# MDR1901VC1 register map
Vendor: Milandr; Series: ARMCM3; File version: 2.0
CPU: CM3 r2p1, little endian, no MPU, no FPU, 3 interrupt priority bits
Registers are 32-bit, read-write, reset 0x0 unless marked. A register's access mark holds for its fields unless they carry their own. Offsets are from the block's base; [hi:lo] are bit positions; {n}, {i} and the like mark numbered series; 'fields as' and 'values as' point back to an identical list.

## MDR_RST_CLOCK — CLock Control
Base 0x40020000
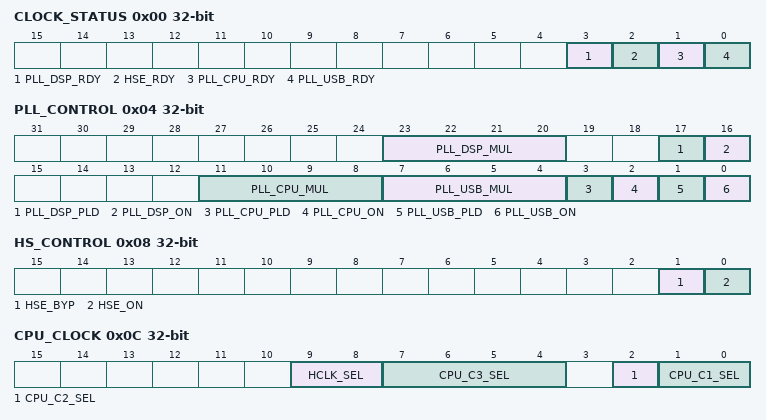
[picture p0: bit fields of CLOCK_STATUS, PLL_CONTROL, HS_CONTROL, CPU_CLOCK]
0x00 CLOCK_STATUS ro
  [3] PLL_DSP_RDY — DSP PLL ready
    0=NotReady (PLL not ready); 1=Ready (PLL ready)
  [2] HSE_RDY — HSE generator ready
    0=NotReady (HSE not ready); 1=Ready (HSE ready)
  [1] PLL_CPU_RDY — PLL CPU ready
    0=NotReady (PLL not ready); 1=Ready (PLL ready)
  [0] PLL_USB_RDY — PLL USP ready
    0=NotReady (PLL not ready); 1=Ready (PLL ready)
0x04 PLL_CONTROL
  [23:20] PLL_DSP_MUL — PLL DSP Mul, [x2 .. x16]
    0=PLL mul x1; {v}=x{v+1} (PLL mul x{v+1}) (v=1..8); 9=PLL mul x10; 10=PLL mul x11; {v}=x{v+1} (PLL mul x{v+1}) (v=11..15)
  [17] PLL_DSP_PLD — PLL DSP Restart
    0=RestartOff (PLL restart inactive); 1=DoRestart (PLL Do Restart)
  [16] PLL_DSP_ON — PLL DSP Enable
    0=Off (PLL Off); 1=On (PLL On)
  [11:8] PLL_CPU_MUL — PLL CPU Mul, [x1 .. x16]
    values as PLL_DSP_MUL
  [7:4] PLL_USB_MUL — PLL USB Mul, [x1 .. x16]
    values as PLL_DSP_MUL
  [3] PLL_CPU_PLD — PLL CPU Restart
    values as PLL_DSP_PLD
  [2] PLL_CPU_ON — PLL CPU Enable
    0=Off (PLL Off); 1=On (PLL On)
  [1] PLL_USB_PLD — PLL USB Restart
    values as PLL_DSP_PLD
  [0] PLL_USB_ON — PLL USB Enable
    0=Off (PLL Off); 1=On (PLL On)
0x08 HS_CONTROL — HSE Generator Control
  [1] HSE_BYP — HSE Bypass Mode
    0=Off (HSE forms Clock from external oscillator); 1=On (HSE passes Clock from external generator)
  [0] HSE_ON — HSE Enable
    0=Off (HSE Off); 1=On (HSE On)
0x0C CPU_CLOCK — CPU Clock Control
  [9:8] HCLK_SEL — Select Clock for CPU
    0=HSI (CPU clock is HSI); 1=CPU_C3 (CPU clock is CPU_C3 output); 2=LSE (CPU clock is LSE); 3=LSI (CPU clock is LSI)
  [7:4] CPU_C3_SEL — CPU_C2 mux output freq devider, [/1, /2, /4 .. /256]
    0b0xxx=div1 (div by 1); 8=div2 (div by 2); 9=div4 (div by 4); 10=div8 (div by 8); 11=div16 (div by 16); 12=div32 (div by 32); 13=div64 (div by 64); 14=div128 (div by 128); 15=div256 (div by 256)
  [2] CPU_C2_SEL — CPU_C2 mux freq select
    0=CPU_C1 (Freq from CPU_C1 mux direct); 1=PLLCPUo (Freq from CPU_C1 mux through PLL)
  [1:0] CPU_C1_SEL — CPU_C1 mux freq select
    0=HSI (CPU_C1 output is HSI); 1=HSI/2 (CPU_C1 output is HSI/2); 2=HSE (CPU_C1 output is HSE); 3=HSE/2 (CPU_C1 output is HSE/2)
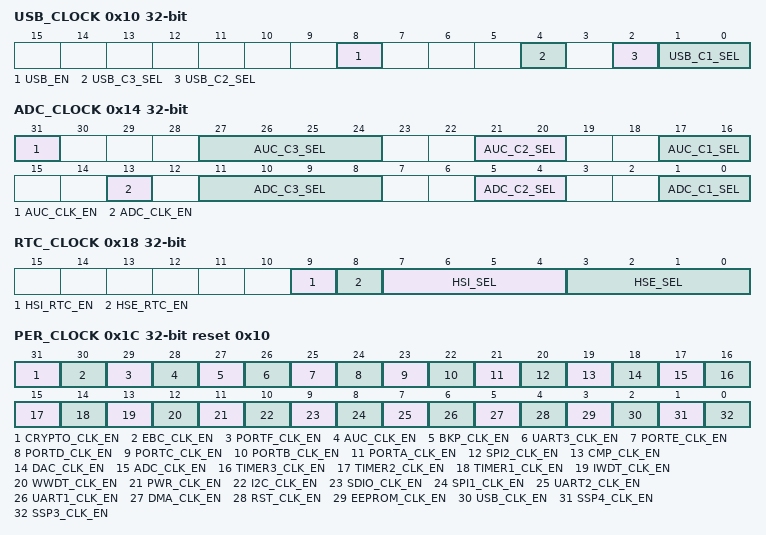
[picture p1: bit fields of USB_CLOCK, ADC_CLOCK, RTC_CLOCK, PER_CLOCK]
0x10 USB_CLOCK — USB Clock Control
  [8] USB_EN — USB Clock Enable
    0=Off (Clock Disabled); 1=On (Clock Enabled)
  [4] USB_C3_SEL — USB_C3 Input Select
    0=USB_C2 (C3 Input is freq from C2); 1=USB_C2_div2 (C3 Input is freq from C2/2)
  [2] USB_C2_SEL — USB_C2 mux freq select
    0=USB_C1 (Freq from CPU_C1 mux direct); 1=PLLUSBo (Freq from CPU_C1 mux through PLL_USB)
  [1:0] USB_C1_SEL — USB_C1 mux freq select
    0=HSI (USB_C1 output is HSI); 1=HSI/2 (USB_C1 output is HSI/2); 2=HSE (USB_C1 output is HSE); 3=HSE/2 (USB_C1 output is HSE/2)
0x14 ADC_CLOCK — ADC Clock Control
  [31] AUC_CLK_EN — AudioCodec Clock Enable
    0=Off (AUC clock disabled); 1=On (AUC clock enabled)
  [27:24] AUC_C3_SEL — AUC_C3 mux input select
    values as CPU_CLOCK.CPU_C3_SEL
  [21:20] AUC_C2_SEL — AUC_C2 mux input select
    0=AUC_C1 (AUC_C2 output is AUC_C1 select); 1=PLLCPUo (AUC_C2 output is PLLCPUo); 2=PLLUSBo (AUC_C2 output is PLLUSBo); 3=No signal from AUC_C2
  [17:16] AUC_C1_SEL — AUC_C1 mux input select
    values as CPU_CLOCK.CPU_C1_SEL
  [13] ADC_CLK_EN — ADC Clock Enable
    0=Off (ADC clock disabled); 1=On (ADC clock enabled)
  [11:8] ADC_C3_SEL — ADC_C2 mux output freq devider, [/1, /2, /4 .. /256]
    values as CPU_CLOCK.CPU_C3_SEL
  [5:4] ADC_C2_SEL — ADC_C2 mux freq select
    0=LSE (ADC_C2 output is LSE); 1=LSI (ADC_C2 output is LSI); 2=ADC_C1 (ADC_C2 output is ADC_C1); 3=HSI_C1 (ADC_C2 output is HSI_C1)
  [1:0] ADC_C1_SEL — ADC_C1 mux freq select
    0=CPU_C1 (ADC_C1 output is CPU_C1); 1=USB_C1 (ADC_C1 output is USB_C1); 2=CPU_C2 (ADC_C1 output is CPU_C2); 3=USB_C2 (ADC_C1 output is USB_C2)
0x18 RTC_CLOCK — RTC Clock Control
  [9] HSI_RTC_EN — RTC HSI Clock enable
    0=Off (RTC HSI Clock Disabled); 1=On (RTC HSI Clock Enabled)
  [8] HSE_RTC_EN — RTC HSE Clock enable
    0=Off (RTC HSE Clock Disabled); 1=On (RTC HSE Clock Enabled)
  [7:4] HSI_SEL — RTC HSI freq devider, [/1, /2, /4 .. /256]
    values as CPU_CLOCK.CPU_C3_SEL
  [3:0] HSE_SEL — RTC HSE freq devider, [/1, /2, /4 .. /256]
    values as CPU_CLOCK.CPU_C3_SEL
0x1C PER_CLOCK reset 0x10 — Peripherials Clock Control
  [all] fields
    0=Off (Clock Disabled); 1=On (Clock Enabled)
  [31] CRYPTO_CLK_EN — CRYPTO Clock Enable
  [30] EBC_CLK_EN — External Bus Clock Enable
  [29] PORTF_CLK_EN — GPIO PORT_F Clock Enable
  [28] AUC_CLK_EN — AUC Clock Enable
  [27] BKP_CLK_EN — Backup Clock Enable
  [26] UART3_CLK_EN — UART3 Clock Enable
  [25] PORTE_CLK_EN — GPIO PORT_E Clock Enable
  [24] PORTD_CLK_EN — GPIO PORT_D Clock Enable
  [23] PORTC_CLK_EN — GPIO PORT_C Clock Enable
  [22] PORTB_CLK_EN — GPIO PORT_B Clock Enable
  [21] PORTA_CLK_EN — GPIO PORT_A Clock Enable
  [20] SPI2_CLK_EN — SPI2 Clock Enable
  [19] CMP_CLK_EN — Comparator Clock Enable
  [18] DAC_CLK_EN — DAC Clock Enable
  [17] ADC_CLK_EN — ADC Clock Enable
  [16] TIMER3_CLK_EN — TIMER3 Clock Enable
  [15] TIMER2_CLK_EN — TIMER2 Clock Enable
  [14] TIMER1_CLK_EN — TIMER1 Clock Enable
  [13] IWDT_CLK_EN — IWDT Clock Enable
  [12] WWDT_CLK_EN — WWDT Clock Enable
  [11] PWR_CLK_EN — Power Clock Enable
  [10] I2C_CLK_EN — I2C Clock Enable
  [9] SDIO_CLK_EN — SDIO Clock Enable
  [8] SPI1_CLK_EN — SPI1 Clock Enable
  [7] UART2_CLK_EN — UART2 Clock Enable
  [6] UART1_CLK_EN — UART1 Clock Enable
  [5] DMA_CLK_EN — DMA Clock Enable
  [4] RST_CLK_EN — RST Clock Enable
  [3] EEPROM_CLK_EN — EEPROM Controller Clock Enable
  [2] USB_CLK_EN — USB Clock Enable
  [1] SSP4_CLK_EN — SSP4 Clock Enable
  [0] SSP3_CLK_EN — SSP3 Clock Enable
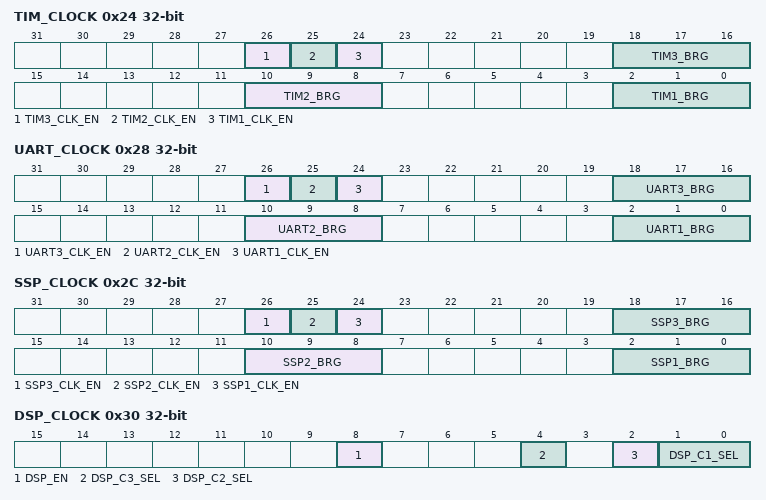
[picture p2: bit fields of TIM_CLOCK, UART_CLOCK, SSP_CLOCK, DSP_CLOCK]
0x24 TIM_CLOCK — Timer's Clock Control
  [26] TIM3_CLK_EN — TIM3_CLOCK enable
    0=Off (Timer3 Clock Disabled); 1=On (Timer3 Clock Enabled)
  [25] TIM2_CLK_EN — TIM2_CLOCK enable
    0=Off (Timer2 Clock Disabled); 1=On (Timer2 Clock Enabled)
  [24] TIM1_CLK_EN — TIM1_CLOCK enable
    0=Off (Timer1 Clock Disabled); 1=On (Timer1 Clock Enabled)
  [18:16] TIM3_BRG — HCLK freq divider to get TIM3_CLOCK, [/1, /2, /4 .. /128]
    0=div1 (div by 1); 1=div2 (div by 2); 2=div4 (div by 4); 3=div8 (div by 8); 4=div16 (div by 16); 5=div32 (div by 32); 6=div64 (div by 64); 7=div128 (div by 128)
  [10:8] TIM2_BRG — HCLK freq divider to get TIM2_CLOCK, [/1, /2, /4 .. /128]
    values as TIM3_BRG
  [2:0] TIM1_BRG — HCLK freq divider to get TIM1_CLOCK, [/1, /2, /4 .. /128]
    values as TIM3_BRG
0x28 UART_CLOCK — UART's Clock Control
  [26] UART3_CLK_EN — UART3_CLOCK enable
    0=Off (UART3 Clock Disabled); 1=On (UART3 Clock Enabled)
  [25] UART2_CLK_EN — UART2_CLOCK enable
    0=Off (UART2 Clock Disabled); 1=On (UART2 Clock Enabled)
  [24] UART1_CLK_EN — UART1_CLOCK enable
    0=Off (UART1 Clock Disabled); 1=On (UART1 Clock Enabled)
  [18:16] UART3_BRG — HCLK freq divider to get UART3_CLOCK, [/1, /2, /4 .. /128]
    values as TIM_CLOCK.TIM3_BRG
  [10:8] UART2_BRG — HCLK freq divider to get UART2_CLOCK, [/1, /2, /4 .. /128]
    values as TIM_CLOCK.TIM3_BRG
  [2:0] UART1_BRG — HCLK freq divider to get UART1_CLOCK, [/1, /2, /4 .. /128]
    values as TIM_CLOCK.TIM3_BRG
0x2C SSP_CLOCK — SSP's Clock Control
  [26] SSP3_CLK_EN — SSP3_CLOCK Enable
    0=Off (SSP3 Clock Disabled); 1=On (SSP3 Clock Enabled)
  [25] SSP2_CLK_EN — SSP2_CLOCK Enable
    0=Off (SSP2 Clock Disabled); 1=On (SSP2 Clock Enabled)
  [24] SSP1_CLK_EN — SSP1_CLOCK Enable
    0=Off (SSP1 Clock Disabled); 1=On (SSP1 Clock Enabled)
  [18:16] SSP3_BRG — HCLK freq divider to get SSP3_CLOCK, [/1, /2, /4 .. /128]
    values as TIM_CLOCK.TIM3_BRG
  [10:8] SSP2_BRG — HCLK freq divider to get SSP2_CLOCK, [/1, /2, /4 .. /128]
    values as TIM_CLOCK.TIM3_BRG
  [2:0] SSP1_BRG — HCLK freq divider to get SSP1_CLOCK, [/1, /2, /4 .. /128]
    values as TIM_CLOCK.TIM3_BRG
0x30 DSP_CLOCK — DSP Clock Control
  [8] DSP_EN — DSP Clock Enable
    0=Off (Clock Disabled); 1=On (Clock Enabled)
  [4] DSP_C3_SEL — DSP_C3 Input Select
    0=DSP_C2 (C3 Input is freq from C2); 1=DSP_C2_div2 (C3 Input is freq from C2/2)
  [2] DSP_C2_SEL — DSP_C2 mux freq select
    0=DSP_C1 (Freq from DSP_C1 mux direct); 1=PLLDSPo (Freq from CPU_C1 mux through PLL_DSP)
  [1:0] DSP_C1_SEL — DSP_C1 mux freq select
    0=HSI (DSP_C1 output is HSI); 1=HSI/2 (DSP_C1 output is HSI/2); 2=HSE (DSP_C1 output is HSE); 3=HSE/2 (DSP_C1 output is HSE/2)
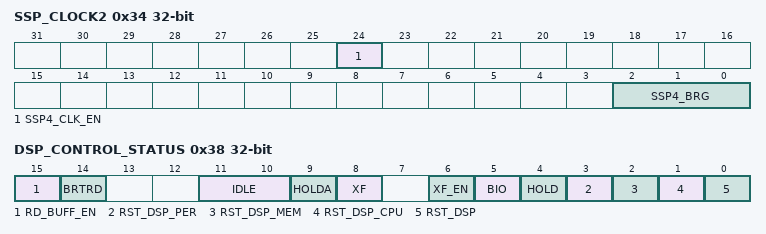
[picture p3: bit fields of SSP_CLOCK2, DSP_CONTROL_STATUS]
0x34 SSP_CLOCK2 — SSP Clock Control 2
  [24] SSP4_CLK_EN — SSP4 Clock Enable
    0=Off (SSP4 Clock Disabled); 1=On (SSP4 Clock Enabled)
  [2:0] SSP4_BRG — HCLK freq divider to get SSP4_CLOCK, [/1, /2, /4 .. /128]
    values as TIM_CLOCK.TIM3_BRG
0x38 DSP_CONTROL_STATUS — DSP Control and Status register
  [15] RD_BUFF_EN — Pre-read DSP Addr space
    0=Off (Pre-Read disabled); 1=On (Pre-Read enabled)
  [14] BRTRD ro — RISC - DSP bridge transfer status
    0=Transfer is performing; 1=Completed (Transfer completed)
  [11:10] IDLE ro — DSP Command Sequencer status
    0=Working (DSP Running); 1=NO_CLOCK_DSP (DSP Clock disabled); 2=NO_CLOCK_DSP_MEM (DSP Core and Memory Clock disabled); 3=NO_CLOCK_DSP_MEM_PER (DSP Core, Memory and Peripherials Clock disabled)
  [9] HOLDA ro — DSP Command Sequencer status
    0=Stopped (Command execution stopped); 1=Running (Commands are executing)
  [8] XF — Flag from DSP to RISC core
    0=Low (Flag Low Level); 1=High (Flag High Level)
  [6] XF_EN — Output flag XF to PA[15] pin
    0=Disable (Flag XF disconnected from PA[15]); 1=Enable (Flag XF connected to PA[15])
  [5] BIO — Flag from RISC to DSP Core
    0=Low (Flag Low Level); 1=High (Flag High Level)
  [4] HOLD — Call to stop DSP command sequencer
    0=DoStop (Request to Stop execution); 1=Inactive (Stop request inactive)
  [3] RST_DSP_PER — Reset DSP Peripherial Blocks
    0=Work (DSP Peripherials are Active); 1=Reset (DSP Peripherials in Reset)
  [2] RST_DSP_MEM — Reset DSP Memory Blocks
    0=Work (DSP memory is Active); 1=Reset (DSP memory disabled)
  [1] RST_DSP_CPU — Reset DSP Core
    0=Work (DSP Core is Active); 1=Reset (DSP Core in Reset)
  [0] RST_DSP — Reset DSP block
    0=Work (DSP Block is Active); 1=Reset (DSP Block in Reset)
